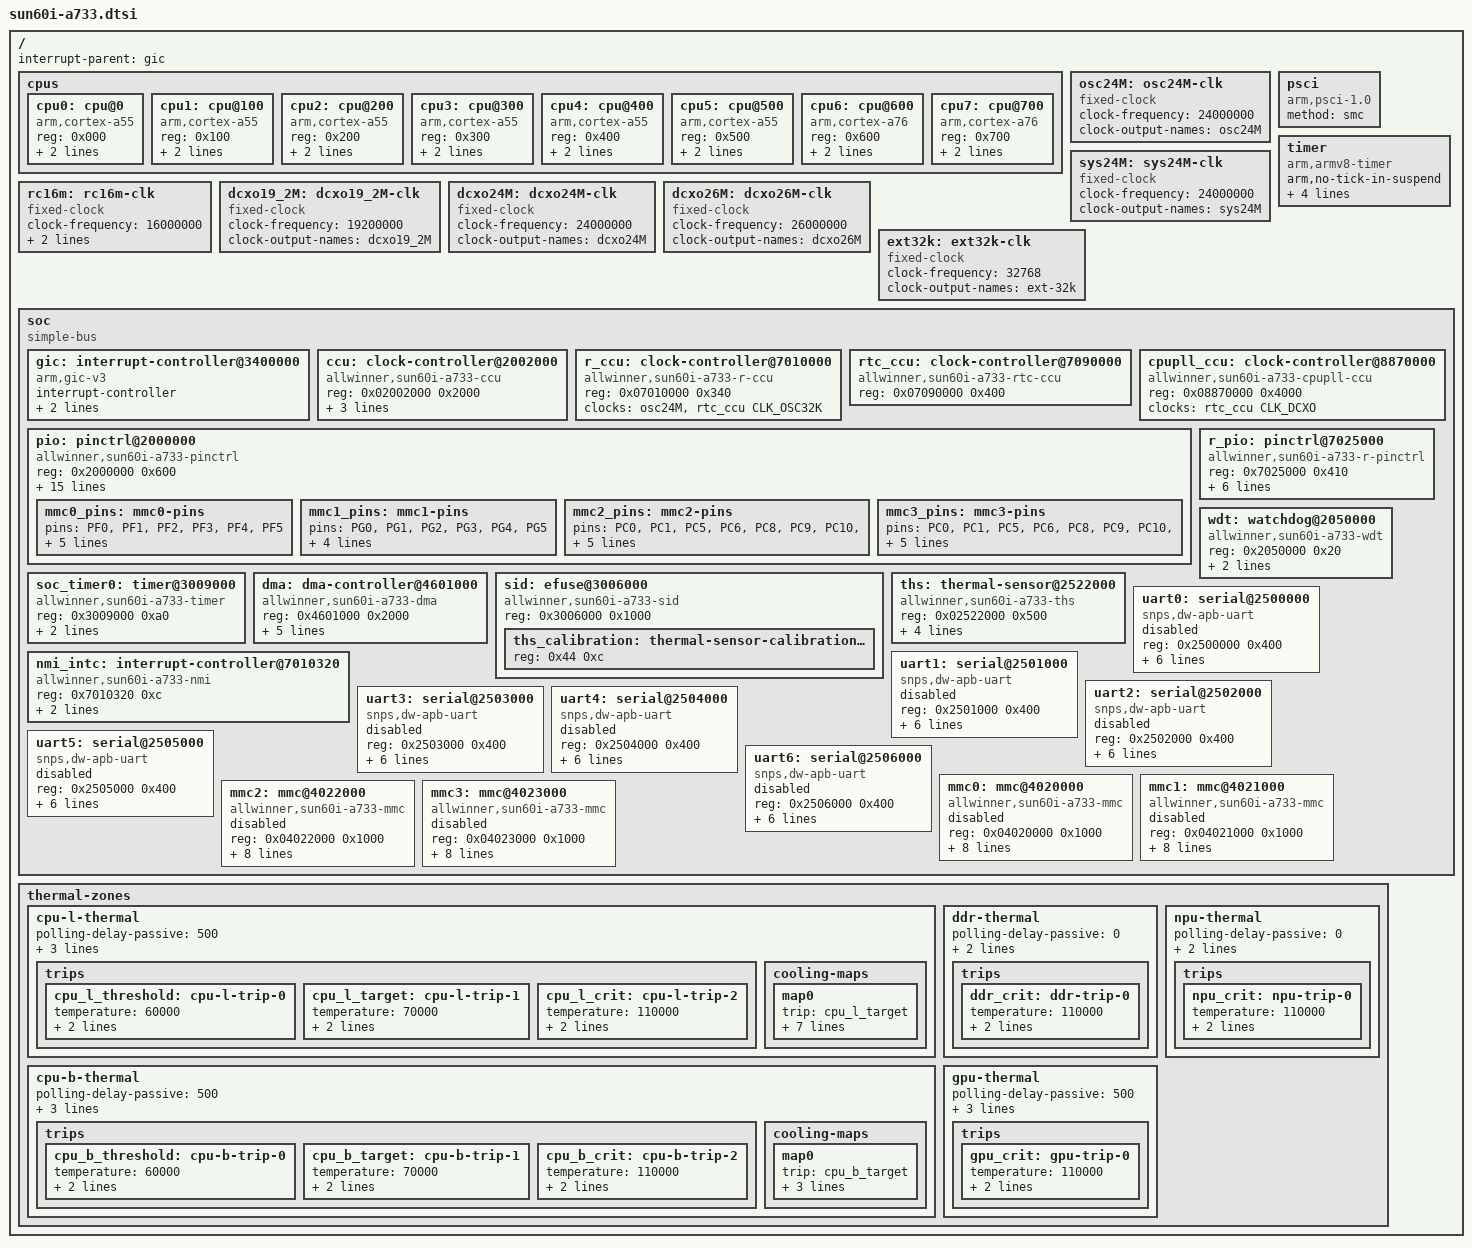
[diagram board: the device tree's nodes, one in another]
/dts-v1/;

#include <dt-bindings/interrupt-controller/arm-gic.h>
#include <dt-bindings/clock/sun60i-a733-ccu.h>
#include <dt-bindings/clock/sun60i-a733-r-ccu.h>
#include <dt-bindings/clock/sun60i-a733-rtc.h>
#include <dt-bindings/clock/sun60i-a733-cpupll-ccu.h>
#include <dt-bindings/reset/sun60i-a733-ccu.h>
#include <dt-bindings/reset/sun60i-a733-r-ccu.h>
#include <dt-bindings/power/sun60i-a733-power.h>
#include <dt-bindings/thermal/thermal.h>

/ {
	interrupt-parent = <&gic>;
	#address-cells = <2>;
	#size-cells = <2>;

	cpus {
		#address-cells = <1>;
		#size-cells = <0>;

		cpu0: cpu@0 {
			compatible = "arm,cortex-a55";
			device_type = "cpu";
			reg = <0x000>;
			enable-method = "psci";
			clocks = <&cpupll_ccu CLK_PLL_CPU_L>;
			#cooling-cells = <2>;
		};

		cpu1: cpu@100 {
			compatible = "arm,cortex-a55";
			device_type = "cpu";
			reg = <0x100>;
			enable-method = "psci";
			clocks = <&cpupll_ccu CLK_PLL_CPU_L>;
			#cooling-cells = <2>;
		};

		cpu2: cpu@200 {
			compatible = "arm,cortex-a55";
			device_type = "cpu";
			reg = <0x200>;
			enable-method = "psci";
			clocks = <&cpupll_ccu CLK_PLL_CPU_L>;
			#cooling-cells = <2>;
		};

		cpu3: cpu@300 {
			compatible = "arm,cortex-a55";
			device_type = "cpu";
			reg = <0x300>;
			enable-method = "psci";
			clocks = <&cpupll_ccu CLK_PLL_CPU_L>;
			#cooling-cells = <2>;
		};

		cpu4: cpu@400 {
			compatible = "arm,cortex-a55";
			device_type = "cpu";
			reg = <0x400>;
			enable-method = "psci";
			clocks = <&cpupll_ccu CLK_PLL_CPU_L>;
			#cooling-cells = <2>;
		};

		cpu5: cpu@500 {
			compatible = "arm,cortex-a55";
			device_type = "cpu";
			reg = <0x500>;
			enable-method = "psci";
			clocks = <&cpupll_ccu CLK_PLL_CPU_L>;
			#cooling-cells = <2>;
		};

		cpu6: cpu@600 {
			compatible = "arm,cortex-a76";
			device_type = "cpu";
			reg = <0x600>;
			enable-method = "psci";
			clocks = <&cpupll_ccu CLK_PLL_CPU_B>;
			#cooling-cells = <2>;
		};

		cpu7: cpu@700 {
			compatible = "arm,cortex-a76";
			device_type = "cpu";
			reg = <0x700>;
			enable-method = "psci";
			clocks = <&cpupll_ccu CLK_PLL_CPU_B>;
			#cooling-cells = <2>;
		};
	};

	osc24M: osc24M-clk {
		#clock-cells = <0>;
		compatible = "fixed-clock";
		clock-frequency = <24000000>;
		clock-output-names = "osc24M";
	};

	sys24M: sys24M-clk {
		#clock-cells = <0>;
		compatible = "fixed-clock";
		clock-frequency = <24000000>;
		clock-output-names = "sys24M";
	};

	rc16m: rc16m-clk {
		#clock-cells = <0>;
		compatible = "fixed-clock";
		clock-frequency = <16000000>;
		clock-accuracy = <300000000>;
		clock-output-names = "rc-16m";
	};

	dcxo19_2M: dcxo19_2M-clk {
		#clock-cells = <0>;
		compatible = "fixed-clock";
		clock-frequency = <19200000>;
		clock-output-names = "dcxo19_2M";
	};

	dcxo24M: dcxo24M-clk {
		#clock-cells = <0>;
		compatible = "fixed-clock";
		clock-frequency = <24000000>;
		clock-output-names = "dcxo24M";
	};

	dcxo26M: dcxo26M-clk {
		#clock-cells = <0>;
		compatible = "fixed-clock";
		clock-frequency = <26000000>;
		clock-output-names = "dcxo26M";
	};

	ext32k: ext32k-clk {
		#clock-cells = <0>;
		compatible = "fixed-clock";
		clock-frequency = <32768>;
		clock-output-names = "ext-32k";
	};

	psci {
		compatible = "arm,psci-1.0";
		method = "smc";
	};

	timer {
		compatible = "arm,armv8-timer";
		arm,no-tick-in-suspend;
		interrupts = <GIC_PPI 13 IRQ_TYPE_LEVEL_HIGH>,
			     <GIC_PPI 14 IRQ_TYPE_LEVEL_HIGH>,
			     <GIC_PPI 11 IRQ_TYPE_LEVEL_HIGH>,
			     <GIC_PPI 10 IRQ_TYPE_LEVEL_HIGH>;
	};

	soc {
		compatible = "simple-bus";
		#address-cells = <1>;
		#size-cells = <1>;
		ranges = <0x0 0x0 0x0 0x40000000>;

		gic: interrupt-controller@3400000 {
			compatible = "arm,gic-v3";
			#interrupt-cells = <3>;
			interrupt-controller;
			reg = <0x03400000 0x10000>,
			      <0x03460000 0x100000>;
			interrupts = <GIC_PPI 9 IRQ_TYPE_LEVEL_HIGH>;
		};

		ccu: clock-controller@2002000 {
			compatible = "allwinner,sun60i-a733-ccu";
			reg = <0x02002000 0x2000>;
			clocks = <&osc24M>, <&rtc_ccu CLK_OSC32K>,
				 <&rtc_ccu CLK_IOSC>, <&rtc_ccu CLK_RTC32K>,
				 <&sys24M>, <&rtc_ccu CLK_DCXO>;
			clock-names = "hosc", "osc32k", "iosc", "rtc32k",
				      "sys24M", "dcxo";
			#clock-cells = <1>;
			#reset-cells = <1>;
		};

		r_ccu: clock-controller@7010000 {
			compatible = "allwinner,sun60i-a733-r-ccu";
			reg = <0x07010000 0x340>;
			clocks = <&osc24M>, <&rtc_ccu CLK_OSC32K>;
			clock-names = "hosc", "losc";
			#clock-cells = <1>;
			#reset-cells = <1>;
		};

		rtc_ccu: clock-controller@7090000 {
			compatible = "allwinner,sun60i-a733-rtc-ccu";
			reg = <0x07090000 0x400>;
			#clock-cells = <1>;
			#reset-cells = <1>;
		};

		cpupll_ccu: clock-controller@8870000 {
			compatible = "allwinner,sun60i-a733-cpupll-ccu";
			reg = <0x08870000 0x4000>;
			clocks = <&rtc_ccu CLK_DCXO>;
			clock-names = "dcxo";
			#clock-cells = <1>;
			#reset-cells = <1>;
		};

		pio: pinctrl@2000000 {
			compatible = "allwinner,sun60i-a733-pinctrl";
			reg = <0x2000000 0x600>;
			interrupts = <GIC_SPI 67 IRQ_TYPE_LEVEL_HIGH>,
				     <GIC_SPI 69 IRQ_TYPE_LEVEL_HIGH>,
				     <GIC_SPI 71 IRQ_TYPE_LEVEL_HIGH>,
				     <GIC_SPI 73 IRQ_TYPE_LEVEL_HIGH>,
				     <GIC_SPI 75 IRQ_TYPE_LEVEL_HIGH>,
				     <GIC_SPI 77 IRQ_TYPE_LEVEL_HIGH>,
				     <GIC_SPI 79 IRQ_TYPE_LEVEL_HIGH>,
				     <GIC_SPI 81 IRQ_TYPE_LEVEL_HIGH>,
				     <GIC_SPI 83 IRQ_TYPE_LEVEL_HIGH>,
				     <GIC_SPI 85 IRQ_TYPE_LEVEL_HIGH>,
				     <GIC_SPI 87 IRQ_TYPE_LEVEL_HIGH>;
			clocks = <&ccu CLK_APB1>, <&osc24M>, <&rtc_ccu CLK_OSC32K>;
			clock-names = "apb", "hosc", "losc";
			gpio-controller;
			#gpio-cells = <3>;
			interrupt-controller;
			#interrupt-cells = <3>;

			/omit-if-no-ref/
			mmc0_pins: mmc0-pins {
				pins = "PF0", "PF1", "PF2", "PF3", "PF4", "PF5";
				allwinner,pinmux = <2>;
				function = "mmc0";
				drive-strength = <30>;
				bias-pull-up;
				power-source = <3300>;
			};

			/omit-if-no-ref/
			mmc1_pins: mmc1-pins {
				pins = "PG0", "PG1", "PG2", "PG3", "PG4", "PG5";
				allwinner,pinmux = <2>;
				function = "mmc1";
				drive-strength = <30>;
				bias-pull-up;
			};

			mmc2_pins: mmc2-pins {
				pins = "PC0", "PC1", "PC5", "PC6", "PC8",
				       "PC9", "PC10", "PC11", "PC13", "PC14",
				       "PC15", "PC16";
				allwinner,pinmux = <3>;
				function = "mmc2";
				drive-strength = <30>;
				bias-pull-up;
			};

			/omit-if-no-ref/
			mmc3_pins: mmc3-pins {
				pins = "PC0", "PC1", "PC5", "PC6", "PC8",
				       "PC9", "PC10", "PC11", "PC13", "PC14",
				       "PC15", "PC16";
				allwinner,pinmux = <4>;
				function = "mmc3";
				drive-strength = <30>;
				bias-pull-up;
			};
		};

		r_pio: pinctrl@7025000 {
			compatible = "allwinner,sun60i-a733-r-pinctrl";
			reg = <0x7025000 0x410>;
			interrupts = <GIC_SPI 198 IRQ_TYPE_LEVEL_HIGH>,
				     <GIC_SPI 200 IRQ_TYPE_LEVEL_HIGH>;
			clocks = <&r_ccu CLK_R_APBS0>, <&osc24M>, <&rtc_ccu CLK_OSC32K>;
			clock-names = "apb", "hosc", "losc";
			gpio-controller;
			#gpio-cells = <3>;
			interrupt-controller;
			#interrupt-cells = <3>;
		};

		wdt: watchdog@2050000 {
			compatible = "allwinner,sun60i-a733-wdt",
				     "allwinner,sun55i-a523-wdt";
			reg = <0x2050000 0x20>;
			interrupts = <GIC_SPI 106 IRQ_TYPE_LEVEL_HIGH>;
			clocks = <&osc24M>, <&rtc_ccu CLK_OSC32K>;
			clock-names = "hosc", "losc";
		};

		soc_timer0: timer@3009000 {
			compatible = "allwinner,sun60i-a733-timer",
				     "allwinner,sun8i-a23-timer";
			reg = <0x3009000 0xa0>;
			interrupts = <GIC_SPI 89 IRQ_TYPE_LEVEL_HIGH>;
			clocks = <&osc24M>;
		};

		dma: dma-controller@4601000 {
			compatible = "allwinner,sun60i-a733-dma",
				     "allwinner,sun50i-a100-dma";
			reg = <0x4601000 0x2000>;
			interrupts = <GIC_SPI 111 IRQ_TYPE_LEVEL_HIGH>;
			clocks = <&ccu CLK_DMA0>, <&ccu CLK_MBUS_DMA0>;
			clock-names = "bus", "mbus";
			dma-channels = <16>;
			dma-requests = <64>;
			resets = <&ccu RST_BUS_DMA0>;
			#dma-cells = <1>;
		};

		sid: efuse@3006000 {
			compatible = "allwinner,sun60i-a733-sid";
			reg = <0x3006000 0x1000>;
			#address-cells = <1>;
			#size-cells = <1>;

			ths_calibration: thermal-sensor-calibration@44 {
				reg = <0x44 0xc>;
			};
		};

		ths: thermal-sensor@2522000 {
			compatible = "allwinner,sun60i-a733-ths";
			reg = <0x02522000 0x500>;
			clocks = <&ccu CLK_THS0>, <&ccu CLK_GPADC0_24M>;
			clock-names = "bus", "mod";
			resets = <&ccu RST_BUS_THS0>;
			nvmem-cells = <&ths_calibration>;
			nvmem-cell-names = "calibration";
			#thermal-sensor-cells = <1>;
		};

		nmi_intc: interrupt-controller@7010320 {
			compatible = "allwinner,sun60i-a733-nmi";
			reg = <0x7010320 0xc>;
			interrupt-controller;
			#interrupt-cells = <2>;
			interrupts = <GIC_SPI 188 IRQ_TYPE_LEVEL_HIGH>;
		};

		uart0: serial@2500000 {
			compatible = "snps,dw-apb-uart";
			reg = <0x2500000 0x400>;
			interrupts = <GIC_SPI 2 IRQ_TYPE_LEVEL_HIGH>;
			reg-shift = <2>;
			reg-io-width = <4>;
			clocks = <&ccu CLK_UART0>;
			resets = <&ccu RST_BUS_UART0>;
			dmas = <&dma 14>, <&dma 14>;
			dma-names = "tx", "rx";
			status = "disabled";
		};

		uart1: serial@2501000 {
			compatible = "snps,dw-apb-uart";
			reg = <0x2501000 0x400>;
			interrupts = <GIC_SPI 3 IRQ_TYPE_LEVEL_HIGH>;
			reg-shift = <2>;
			reg-io-width = <4>;
			clocks = <&ccu CLK_UART1>;
			resets = <&ccu RST_BUS_UART1>;
			dmas = <&dma 15>, <&dma 15>;
			dma-names = "tx", "rx";
			status = "disabled";
		};

		uart2: serial@2502000 {
			compatible = "snps,dw-apb-uart";
			reg = <0x2502000 0x400>;
			interrupts = <GIC_SPI 4 IRQ_TYPE_LEVEL_HIGH>;
			reg-shift = <2>;
			reg-io-width = <4>;
			clocks = <&ccu CLK_UART2>;
			resets = <&ccu RST_BUS_UART2>;
			dmas = <&dma 16>, <&dma 16>;
			dma-names = "tx", "rx";
			status = "disabled";
		};

		uart3: serial@2503000 {
			compatible = "snps,dw-apb-uart";
			reg = <0x2503000 0x400>;
			interrupts = <GIC_SPI 5 IRQ_TYPE_LEVEL_HIGH>;
			reg-shift = <2>;
			reg-io-width = <4>;
			clocks = <&ccu CLK_UART3>;
			resets = <&ccu RST_BUS_UART3>;
			dmas = <&dma 17>, <&dma 17>;
			dma-names = "tx", "rx";
			status = "disabled";
		};

		uart4: serial@2504000 {
			compatible = "snps,dw-apb-uart";
			reg = <0x2504000 0x400>;
			interrupts = <GIC_SPI 6 IRQ_TYPE_LEVEL_HIGH>;
			reg-shift = <2>;
			reg-io-width = <4>;
			clocks = <&ccu CLK_UART4>;
			resets = <&ccu RST_BUS_UART4>;
			dmas = <&dma 18>, <&dma 18>;
			dma-names = "tx", "rx";
			status = "disabled";
		};

		uart5: serial@2505000 {
			compatible = "snps,dw-apb-uart";
			reg = <0x2505000 0x400>;
			interrupts = <GIC_SPI 7 IRQ_TYPE_LEVEL_HIGH>;
			reg-shift = <2>;
			reg-io-width = <4>;
			clocks = <&ccu CLK_UART5>;
			resets = <&ccu RST_BUS_UART5>;
			dmas = <&dma 19>, <&dma 19>;
			dma-names = "tx", "rx";
			status = "disabled";
		};

		uart6: serial@2506000 {
			compatible = "snps,dw-apb-uart";
			reg = <0x2506000 0x400>;
			interrupts = <GIC_SPI 8 IRQ_TYPE_LEVEL_HIGH>;
			reg-shift = <2>;
			reg-io-width = <4>;
			clocks = <&ccu CLK_UART6>;
			resets = <&ccu RST_BUS_UART6>;
			dmas = <&dma 20>, <&dma 20>;
			dma-names = "tx", "rx";
			status = "disabled";
		};

		mmc0: mmc@4020000 {
			compatible = "allwinner,sun60i-a733-mmc",
				     "allwinner,sun20i-d1-mmc";
			reg = <0x04020000 0x1000>;
			clocks = <&ccu CLK_BUS_SMHC0>, <&ccu CLK_SMHC0>;
			clock-names = "ahb", "mmc";
			resets = <&ccu RST_BUS_SMHC0>;
			reset-names = "ahb";
			interrupts = <GIC_SPI 161 IRQ_TYPE_LEVEL_HIGH>;
			pinctrl-names = "default";
			pinctrl-0 = <&mmc0_pins>;
			status = "disabled";

			max-frequency = <150000000>;
			cap-sd-highspeed;
			cap-mmc-highspeed;
			cap-sdio-irq;
			#address-cells = <1>;
			#size-cells = <0>;
		};

		mmc1: mmc@4021000 {
			compatible = "allwinner,sun60i-a733-mmc",
				     "allwinner,sun20i-d1-mmc";
			reg = <0x04021000 0x1000>;
			clocks = <&ccu CLK_BUS_SMHC1>, <&ccu CLK_SMHC1>;
			clock-names = "ahb", "mmc";
			resets = <&ccu RST_BUS_SMHC1>;
			reset-names = "ahb";
			interrupts = <GIC_SPI 162 IRQ_TYPE_LEVEL_HIGH>;
			pinctrl-names = "default";
			pinctrl-0 = <&mmc1_pins>;
			status = "disabled";

			max-frequency = <150000000>;
			cap-sd-highspeed;
			cap-mmc-highspeed;
			cap-sdio-irq;
			#address-cells = <1>;
			#size-cells = <0>;
		};

		mmc2: mmc@4022000 {
			compatible = "allwinner,sun60i-a733-mmc",
				     "allwinner,sun20i-d1-mmc";
			reg = <0x04022000 0x1000>;
			clocks = <&ccu CLK_BUS_SMHC2>, <&ccu CLK_SMHC2>;
			clock-names = "ahb", "mmc";
			resets = <&ccu RST_BUS_SMHC2>;
			reset-names = "ahb";
			interrupts = <GIC_SPI 163 IRQ_TYPE_LEVEL_HIGH>;
			pinctrl-names = "default";
			pinctrl-0 = <&mmc2_pins>;
			status = "disabled";

			max-frequency = <150000000>;
			cap-sd-highspeed;
			cap-mmc-highspeed;
			cap-sdio-irq;
			#address-cells = <1>;
			#size-cells = <0>;
		};

		mmc3: mmc@4023000 {
			compatible = "allwinner,sun60i-a733-mmc",
				     "allwinner,sun20i-d1-mmc";
			reg = <0x04023000 0x1000>;
			clocks = <&ccu CLK_BUS_SMHC3>, <&ccu CLK_SMHC3>;
			clock-names = "ahb", "mmc";
			resets = <&ccu RST_BUS_SMHC3>;
			reset-names = "ahb";
			interrupts = <GIC_SPI 164 IRQ_TYPE_LEVEL_HIGH>;
			pinctrl-names = "default";
			pinctrl-0 = <&mmc3_pins>;
			status = "disabled";

			max-frequency = <150000000>;
			cap-sd-highspeed;
			cap-mmc-highspeed;
			cap-sdio-irq;
			#address-cells = <1>;
			#size-cells = <0>;
		};
	};

	thermal-zones {
		cpu-l-thermal {
			polling-delay-passive = <500>;
			polling-delay = <1000>;
			thermal-sensors = <&ths 3>;
			sustainable-power = <756>;

			trips {
				cpu_l_threshold: cpu-l-trip-0 {
					temperature = <60000>;
					type = "passive";
					hysteresis = <0>;
				};
				cpu_l_target: cpu-l-trip-1 {
					temperature = <70000>;
					type = "passive";
					hysteresis = <0>;
				};
				cpu_l_crit: cpu-l-trip-2 {
					temperature = <110000>;
					type = "critical";
					hysteresis = <0>;
				};
			};

			cooling-maps {
				map0 {
					trip = <&cpu_l_target>;
					cooling-device = <&cpu0 THERMAL_NO_LIMIT THERMAL_NO_LIMIT>,
							 <&cpu1 THERMAL_NO_LIMIT THERMAL_NO_LIMIT>,
							 <&cpu2 THERMAL_NO_LIMIT THERMAL_NO_LIMIT>,
							 <&cpu3 THERMAL_NO_LIMIT THERMAL_NO_LIMIT>,
							 <&cpu4 THERMAL_NO_LIMIT THERMAL_NO_LIMIT>,
							 <&cpu5 THERMAL_NO_LIMIT THERMAL_NO_LIMIT>;
				};
			};
		};

		cpu-b-thermal {
			polling-delay-passive = <500>;
			polling-delay = <1000>;
			thermal-sensors = <&ths 0>;
			sustainable-power = <914>;

			trips {
				cpu_b_threshold: cpu-b-trip-0 {
					temperature = <60000>;
					type = "passive";
					hysteresis = <0>;
				};
				cpu_b_target: cpu-b-trip-1 {
					temperature = <70000>;
					type = "passive";
					hysteresis = <0>;
				};
				cpu_b_crit: cpu-b-trip-2 {
					temperature = <110000>;
					type = "critical";
					hysteresis = <0>;
				};
			};

			cooling-maps {
				map0 {
					trip = <&cpu_b_target>;
					cooling-device = <&cpu6 THERMAL_NO_LIMIT THERMAL_NO_LIMIT>,
							 <&cpu7 THERMAL_NO_LIMIT THERMAL_NO_LIMIT>;
				};
			};
		};

		ddr-thermal {
			polling-delay-passive = <0>;
			polling-delay = <0>;
			thermal-sensors = <&ths 1>;

			trips {
				ddr_crit: ddr-trip-0 {
					temperature = <110000>;
					type = "critical";
					hysteresis = <0>;
				};
			};
		};

		npu-thermal {
			polling-delay-passive = <0>;
			polling-delay = <0>;
			thermal-sensors = <&ths 2>;

			trips {
				npu_crit: npu-trip-0 {
					temperature = <110000>;
					type = "critical";
					hysteresis = <0>;
				};
			};
		};

		gpu-thermal {
			polling-delay-passive = <500>;
			polling-delay = <1000>;
			thermal-sensors = <&ths 4>;
			sustainable-power = <2400>;

			trips {
				gpu_crit: gpu-trip-0 {
					temperature = <110000>;
					type = "critical";
					hysteresis = <0>;
				};
			};
		};
	};
};
